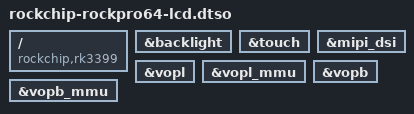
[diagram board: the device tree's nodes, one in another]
//For RockPro64 7″ LCD TOUCH SCREEN PANEL

/dts-v1/;
/plugin/;

/ {
  compatible = "rockchip,rk3399";
	
  fragment@0 {
    target=<&backlight>;
    __overlay__ {
      status = "okay";
    };
  };
  
  fragment@1 {
    target=<&touch>;
    __overlay__ {
      status = "okay";
    };
  };
  
  fragment@2 {
    target=<&mipi_dsi>;
    __overlay__ {
      status = "okay";
    };
  }; 
  
  fragment@3 {
    target=<&vopl>;
    __overlay__ {
      status = "okay";
    };
  };

  fragment@4 {
    target=<&vopl_mmu>;
    __overlay__ {
      status = "okay";
    };
  };
  
  fragment@5 {
    target=<&vopb>;
    __overlay__ {
      status = "okay";
    };
  };

  fragment@6 {
    target=<&vopb_mmu>;
    __overlay__ {
      status = "okay";
    };
  };
};

